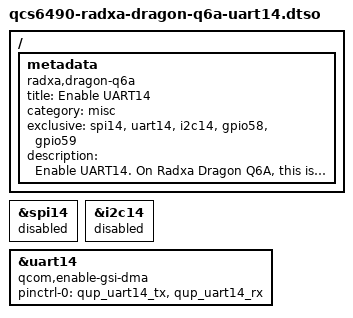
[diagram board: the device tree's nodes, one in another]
// SPDX-License-Identifier: BSD-3-Clause
/*
 * Copyright (c) 2026 Radxa Computer (Shenzhen) Co., Ltd.
 */

/dts-v1/;
/plugin/;

/ {
	metadata {
		title = "Enable UART14";
		compatible = "radxa,dragon-q6a";
		category = "misc";
		exclusive = "spi14", "uart14", "i2c14", "gpio58", "gpio59";
		description = "Enable UART14.
On Radxa Dragon Q6A, this is pin 37(tx), 36(rx).";
	};
};

&spi14 {
	status = "disabled";
};

&i2c14 {
	status = "disabled";
};

&uart14 {
	qcom,enable-gsi-dma;
	status = "okay";
	pinctrl-0 = <&qup_uart14_tx>, <&qup_uart14_rx>;
};
